# G32R501 register map
Vendor: Geehy Semiconductor Co., Ltd.; Series: G32R5; File version: 1.0
CPU: CM55 r0p1, little endian, MPU, FPU, double-precision FPU, DSP, VTOR, 4 interrupt priority bits
Registers are 32-bit, read-write, reset 0x0 unless marked. A register's access mark holds for its fields unless they carry their own. Offsets are from the block's base; [hi:lo] are bit positions; {n}, {i} and the like mark numbered series; 'fields as' and 'values as' point back to an identical list.

## PWM1 — Pulse Width Modulator
Base 0x40000000
Same registers: PWM2 0x40000400, PWM3 0x40000800, PWM4 0x40000C00, PWM5 0x40001000, PWM6 0x40001400, PWM7 0x40001800, PWM8 0x40001C00
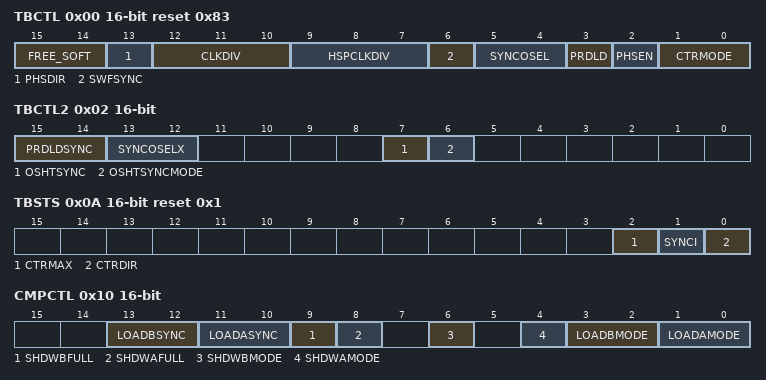
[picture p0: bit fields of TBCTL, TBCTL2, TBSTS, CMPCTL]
0x00 TBCTL 16-bit reset 0x83 — Time Base Control Register
  [15:14] FREE_SOFT — Emulation Mode Bits.
  [13] PHSDIR — Phase Direction Bit
  [12:10] CLKDIV — Time Base Clock Pre-Scale Bits
  [9:7] HSPCLKDIV — High Speed Time Base Clock Pre-Scale Bits
  [6] SWFSYNC — Software Forced Sync Pulse
  [5:4] SYNCOSEL — Sync Output Select
  [3] PRDLD — Active Period Reg Load from Shadow Select
  [2] PHSEN — Counter Reg Load from Phase Reg Enable
  [1:0] CTRMODE — Counter Mode
0x02 TBCTL2 16-bit — Time Base Control Register 2
  [15:14] PRDLDSYNC — Shadow to Active Period on SYNC event
  [13:12] SYNCOSELX — Extended selection bits for SYNCOUT
  [7] OSHTSYNC — Oneshot sync bit
  [6] OSHTSYNCMODE — Oneshot sync enable bit
0x08 TBCTR 16-bit — Time Base Counter Register
0x0A TBSTS 16-bit reset 0x1 — Time Base Status Register
  [2] CTRMAX — Time-Base Counter Max Latched Status Bit
  [1] SYNCI — Input Synchronization Latched Status Bit
  [0] CTRDIR ro — Time Base Counter Direction Status Bit
0x10 CMPCTL 16-bit — Counter Compare Control Register
  [13:12] LOADBSYNC — Shadow to Active CMPB Register Load on SYNC event
  [11:10] LOADASYNC — Shadow to Active CMPA Register Load on SYNC event
  [9] SHDWBFULL ro — Counter-compare B (CMPB) Shadow Register Full Status Flag
  [8] SHDWAFULL ro — Counter-compare A (CMPA) Shadow Register Full Status Flag
  [6] SHDWBMODE — Counter-compare B (CMPB) Register Operating Mode
  [4] SHDWAMODE — Counter-compare A (CMPA) Register Operating Mode
  [3:2] LOADBMODE — Active Counter-Compare B (CMPB) Load From Shadow Select Mode
  [1:0] LOADAMODE — Active Counter-Compare A (CMPA) Load From Shadow Select Mode
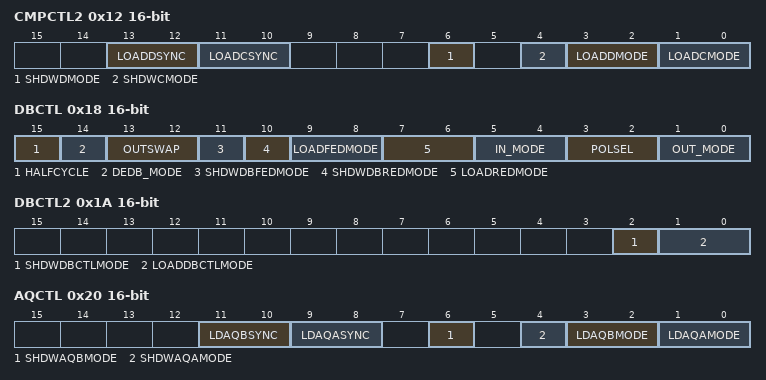
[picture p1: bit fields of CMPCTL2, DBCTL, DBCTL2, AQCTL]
0x12 CMPCTL2 16-bit — Counter Compare Control Register 2
  [13:12] LOADDSYNC — Shadow to Active CMPD Register Load on SYNC event
  [11:10] LOADCSYNC — Shadow to Active CMPC Register Load on SYNC event
  [6] SHDWDMODE — Counter-Compare D Register Operating Mode
  [4] SHDWCMODE — Counter-Compare C Register Operating Mode
  [3:2] LOADDMODE — Active Counter-Compare D (CMPD) Load from Shadow Select Mode
  [1:0] LOADCMODE — Active Counter-Compare C (CMPC) Load from Shadow Select Mode
0x18 DBCTL 16-bit — Dead-Band Generator Control Register
  [15] HALFCYCLE — Half Cycle Clocking Enable Bit
  [14] DEDB_MODE — Dead Band Dual-Edge B Mode Control (S8 switch)
  [13:12] OUTSWAP — Dead Band Output Swap Control
  [11] SHDWDBFEDMODE — FED Dead-Band Load Mode
  [10] SHDWDBREDMODE — RED Dead-Band Load Mode
  [9:8] LOADFEDMODE — Active DBFED Load from Shadow Select Mode
  [7:6] LOADREDMODE — Active DBRED Load from Shadow Select Mode
  [5:4] IN_MODE — Dead-Band Input Mode Control
  [3:2] POLSEL — Polarity Select Control
  [1:0] OUT_MODE — Dead-Band Output Mode Control
0x1A DBCTL2 16-bit — Dead-Band Generator Control Register 2
  [2] SHDWDBCTLMODE — DBCTL Load Mode
  [1:0] LOADDBCTLMODE — Active DBCTL Load from Shadow Select Mode
0x20 AQCTL 16-bit — Action Qualifier Control Register
  [11:10] LDAQBSYNC — Shadow to Active AQCTLB Register Load on SYNC event
  [9:8] LDAQASYNC — Shadow to Active AQCTLA Register Load on SYNC event
  [6] SHDWAQBMODE — Action Qualifier B Register operating mode
  [4] SHDWAQAMODE — Action Qualifier A Register operating mode
  [3:2] LDAQBMODE — Active Action Qualifier B Load from Shadow Select Mode
  [1:0] LDAQAMODE — Active Action Qualifier A Load from Shadow Select Mode
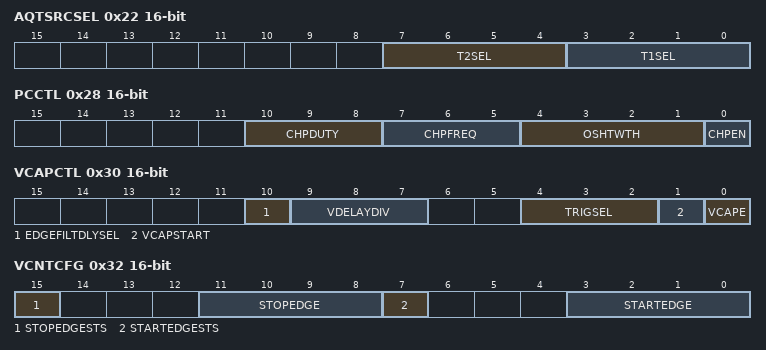
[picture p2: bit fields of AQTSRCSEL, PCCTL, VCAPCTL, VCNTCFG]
0x22 AQTSRCSEL 16-bit — Action Qualifier Trigger Event Source Select Register
  [7:4] T2SEL — T2 Event Source Select Bits
  [3:0] T1SEL — T1 Event Source Select Bits
0x28 PCCTL 16-bit — PWM Chopper Control Register
  [10:8] CHPDUTY — Chopping Clock Duty Cycle
  [7:5] CHPFREQ — Chopping Clock Frequency
  [4:1] OSHTWTH — One-Shot Pulse Width
  [0] CHPEN — PWM-Chopping Enable
0x30 VCAPCTL 16-bit — Valley Capture Control Register
  [10] EDGEFILTDLYSEL — Valley Switching Mode Delay Selection
  [9:7] VDELAYDIV — Valley Delay Mode Divide Enable
  [4:2] TRIGSEL — Status of Numbered of Captured Events
  [1] VCAPSTART — Valley Capture Start
  [0] VCAPE — Valley Capture Enable/Disable
0x32 VCNTCFG 16-bit — Valley Counter Config Register
  [15] STOPEDGESTS ro — Stop Edge Status Bit
  [11:8] STOPEDGE — Counter Stop Edge Selection
  [7] STARTEDGESTS ro — Start Edge Status Bit
  [3:0] STARTEDGE — Counter Start Edge Selection
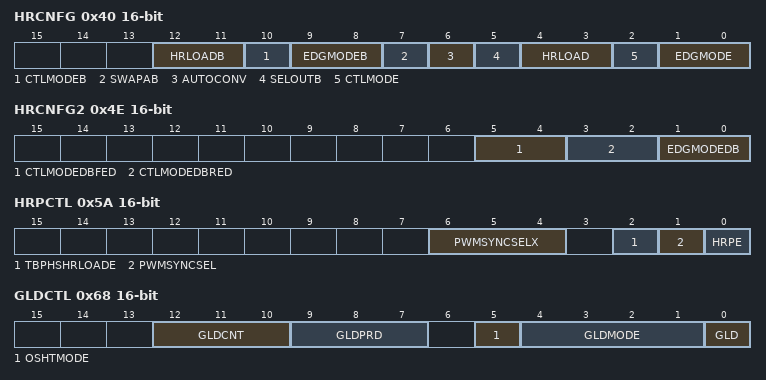
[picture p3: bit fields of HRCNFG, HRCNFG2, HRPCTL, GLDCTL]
0x40 HRCNFG 16-bit — HRPWM Configuration Register
  [12:11] HRLOADB — Shadow Mode Bit
  [10] CTLMODEB — Control Mode Bits
  [9:8] EDGMODEB — Edge Mode Bits
  [7] SWAPAB — Swap PWM A & B Output Signals
  [6] AUTOCONV — Auto Convert Delay Line Value
  [5] SELOUTB — PWMxB Output Select Bit
  [4:3] HRLOAD — Shadow Mode Bit
  [2] CTLMODE — Control Mode Bits
  [1:0] EDGMODE — Edge Mode Bits
0x42 HRPWR 16-bit — HRPWM Power Register
  [15] CALPWRON — MEP Calibration Power Bits (only available on PWM1)
0x4C HRMSTEP 16-bit — HRPWM MEP Step Register
  [7:0] HRMSTEP — High Resolution MEP Step
0x4E HRCNFG2 16-bit — HRPWM Configuration 2 Register
  [5:4] CTLMODEDBFED — Shadow Mode Bit - selection should match DBCTL LOADFEDMODE
  [3:2] CTLMODEDBRED — Shadow Mode Bit - selection should match DBCTL LOADREDMODE
  [1:0] EDGMODEDB — Edge Mode Bits
0x5A HRPCTL 16-bit — High Resolution Period Control Register
  [6:4] PWMSYNCSELX — Extended selection bits for PWMSYNCPER
  [2] TBPHSHRLOADE — TBPHSHR Load Enable
  [1] PWMSYNCSEL — PWMSYNC Source Select Bit
  [0] HRPE — High Resolution Period Enable Bit
0x5C TRREM 16-bit — HRPWM High Resolution Remainder Register
  [10:0] TRREM — Translator Remainder Bits
0x68 GLDCTL 16-bit — Global PWM Load Control Register
  [12:10] GLDCNT ro — Global Load Strobe Counter Register
  [9:7] GLDPRD — Global Load Strobe Period Select Register
  [5] OSHTMODE — One Shot Load Mode Control Bit
  [4:1] GLDMODE — Global Load Pulse selection for Shadow to Active Mode Reloads
  [0] GLD — Global Shadow to Active Load Event Control
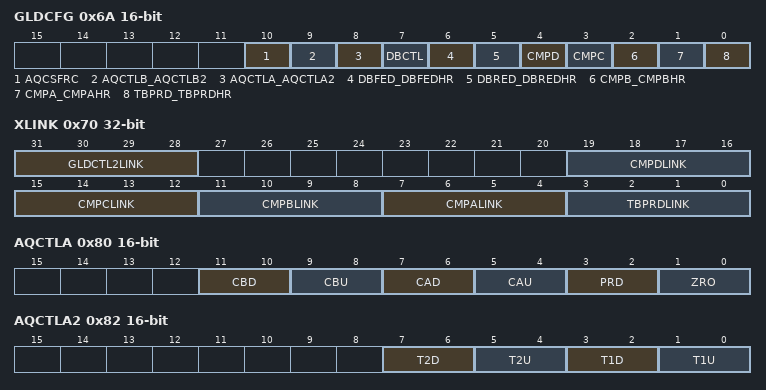
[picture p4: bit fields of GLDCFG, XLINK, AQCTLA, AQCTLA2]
0x6A GLDCFG 16-bit — Global PWM Load Config Register
  [10] AQCSFRC — Global load event configuration for AQCSFRC
  [9] AQCTLB_AQCTLB2 — Global load event configuration for AQCTLB_AQCTLB2
  [8] AQCTLA_AQCTLA2 — Global load event configuration for AQCTLA_AQCTLA2
  [7] DBCTL — Global load event configuration for DBCTL
  [6] DBFED_DBFEDHR — Global load event configuration for DBFED_DBFEDHR
  [5] DBRED_DBREDHR — Global load event configuration for DBRED_DBREDHR
  [4] CMPD — Global load event configuration for CMPD
  [3] CMPC — Global load event configuration for CMPC
  [2] CMPB_CMPBHR — Global load event configuration for CMPB_CMPBHR
  [1] CMPA_CMPAHR — Global load event configuration for CMPA_CMPAHR
  [0] TBPRD_TBPRDHR — Global load event configuration for TBPRD_TBPRDHR
0x70 XLINK — PWMx Link Register
  [31:28] GLDCTL2LINK — GLDCTL2 Link Bits
  [19:16] CMPDLINK — CMPD Link Bits
  [15:12] CMPCLINK — CMPC Link Bits
  [11:8] CMPBLINK — CMPB_CMPBHR Link Bits
  [7:4] CMPALINK — CMPA_CMPAHR Link Bits
  [3:0] TBPRDLINK — TBPRD_TBPRDHR Link Bits
0x80 AQCTLA 16-bit — Action Qualifier Control Register For Output A
  [11:10] CBD — Action When TBCTR = CMPB on Down Count
  [9:8] CBU — Action When TBCTR = CMPB on Up Count
  [7:6] CAD — Action When TBCTR = CMPA on Down Count
  [5:4] CAU — Action When TBCTR = CMPA on Up Count
  [3:2] PRD — Action When TBCTR = TBPRD
  [1:0] ZRO — Action When TBCTR = 0
0x82 AQCTLA2 16-bit — Additional Action Qualifier Control Register For Output A
  [7:6] T2D — Action when event occurs on T2 in DOWN-Count
  [5:4] T2U — Action when event occurs on T2 in UP-Count
  [3:2] T1D — Action when event occurs on T1 in DOWN-Count
  [1:0] T1U — Action when event occurs on T1 in UP-Count
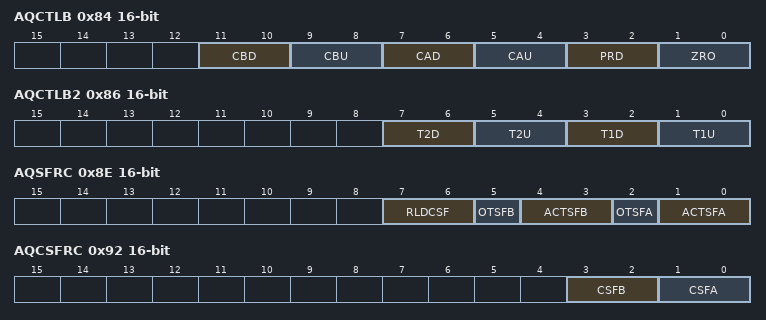
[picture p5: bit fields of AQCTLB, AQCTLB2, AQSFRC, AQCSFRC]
0x84 AQCTLB 16-bit — Action Qualifier Control Register For Output B
  fields as AQCTLA
0x86 AQCTLB2 16-bit — Additional Action Qualifier Control Register For Output B
  fields as AQCTLA2
0x8E AQSFRC 16-bit — Action Qualifier Software Force Register
  [7:6] RLDCSF — AQCSFRC Active Register Reload From Shadow Options
  [5] OTSFB — One-Time Software Forced Event on Output B
  [4:3] ACTSFB — Action When One-Time Software Force B is Invoked
  [2] OTSFA — One-Time Software Forced Event on Output A
  [1:0] ACTSFA — Action When One-Time Software Force A Is Invoked
0x92 AQCSFRC 16-bit — Action Qualifier Continuous S/W Force Register
  [3:2] CSFB — Continuous Software Force on Output B
  [1:0] CSFA — Continuous Software Force on Output A
0xA0 DBREDHR 16-bit — Dead-Band Generator Rising Edge Delay High Resolution Mirror Register
  [15:9] DBREDHR — Dead Band Rising Edge Delay High Resolution Bits
0xA2 DBRED 16-bit — Dead-Band Generator Rising Edge Delay High Resolution Mirror Register
  [13:0] DBRED — Rising edge delay value
0xA4 DBFEDHR 16-bit — Dead-Band Generator Falling Edge Delay High Resolution Register
  [15:9] DBFEDHR — Dead Band Falling Edge Delay High Resolution Bits
0xA6 DBFED 16-bit — Dead-Band Generator Falling Edge Delay Count Register
  [13:0] DBFED — Falling Edge Delay Count
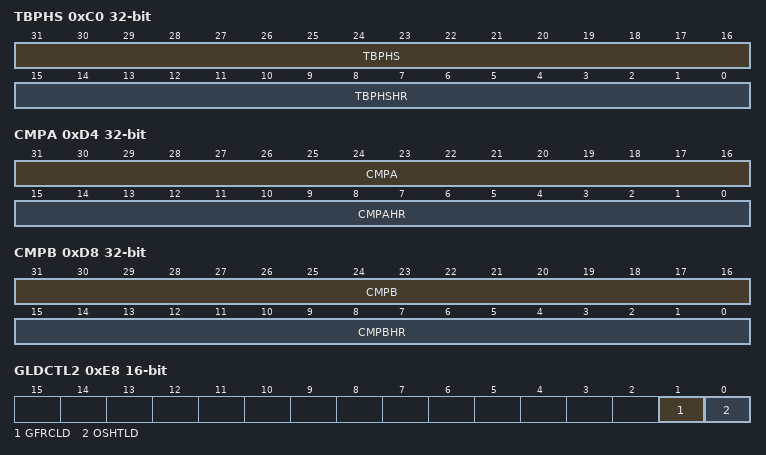
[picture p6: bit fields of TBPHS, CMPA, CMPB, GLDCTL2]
0xC0 TBPHS — Time Base Phase High
  [31:16] TBPHS — Phase Offset Register
  [15:0] TBPHSHR — Phase Offset (High Resolution) Register.
0xC4 TBPRDHR 16-bit — Time Base Period High Resolution Register
  [15:0] TBPRDHR — Period High Resolution Bits
0xC6 TBPRD 16-bit — Time Base Period Register
0xD4 CMPA — Counter Compare A Register
  [31:16] CMPA — Compare A Register
  [15:0] CMPAHR — Compare A HRPWM Extension Register
0xD8 CMPB — Compare B Register
  [31:16] CMPB — Compare B Register
  [15:0] CMPBHR — Compare B High Resolution Bits
0xDE CMPC 16-bit — Counter Compare C Register
  [15:0] CMPC — Compare C Register
0xE2 CMPD 16-bit — Counter Compare D Register
  [15:0] CMPD — Compare D Register
0xE8 GLDCTL2 16-bit — Global PWM Load Control Register 2
  [1] GFRCLD — Force Load Event in One Shot Mode
  [0] OSHTLD — Enable Reload Event in One Shot Mode
0xEE SWVDELVAL 16-bit — Software Valley Mode Delay Register
  [15:0] SWVDELVAL — Software Valley Delay Value Register
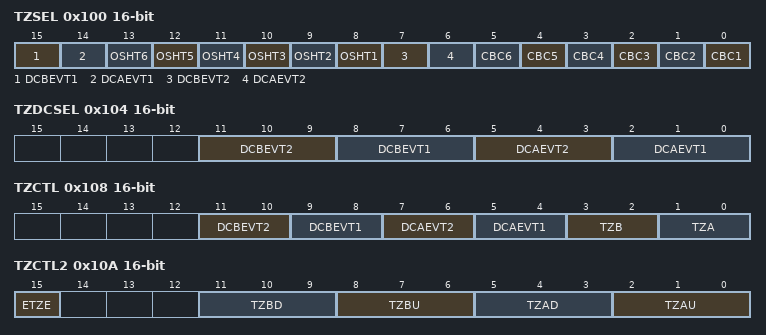
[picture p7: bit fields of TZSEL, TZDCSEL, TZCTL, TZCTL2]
0x100 TZSEL 16-bit — Trip Zone Select Register
  [15] DCBEVT1 — Digital Compare Output B Event 1 Select
  [14] DCAEVT1 — Digital Compare Output A Event 1 Select
  [n+7] OSHT{n} (n=1..6) — Trip-zone {n} (TZ{n}) Select
  [7] DCBEVT2 — Digital Compare Output B Event 2 Select
  [6] DCAEVT2 — Digital Compare Output A Event 2 Select
  [n-1] CBC{n} (n=1..6) — Trip-zone {n} (TZ{n}) Select
0x104 TZDCSEL 16-bit — Trip Zone Digital Comparator Select Register
  [11:9] DCBEVT2 — Digital Compare Output B Event 2 Selection
  [8:6] DCBEVT1 — Digital Compare Output B Event 1 Selection
  [5:3] DCAEVT2 — Digital Compare Output A Event 2 Selection
  [2:0] DCAEVT1 — Digital Compare Output A Event 1 Selection
0x108 TZCTL 16-bit — Trip Zone Control Register
  [11:10] DCBEVT2 — Digital Compare Output B Event 2 Action On PWMxB
  [9:8] DCBEVT1 — Digital Compare Output B Event 1 Action On PWMxB
  [7:6] DCAEVT2 — Digital Compare Output A Event 2 Action On PWMxA
  [5:4] DCAEVT1 — Digital Compare Output A Event 1 Action On PWMxA
  [3:2] TZB — TZ1 to TZ6, DCAEVT1/2, DCBEVT1/2Trip Action On PWMxB
  [1:0] TZA — TZ1 to TZ6, DCAEVT1/2, DCBEVT1/2Trip Action On PWMxA
0x10A TZCTL2 16-bit — Additional Trip Zone Control Register
  [15] ETZE — TZCTL2 Enable
  [11:9] TZBD — TZ1 to TZ6, DCAEVT1/2, DCBEVT1/2 Trip Action On PWMxB
  [8:6] TZBU — TZ1 to TZ6, DCAEVT1/2, DCBEVT1/2 Trip Action On PWMxB
  [5:3] TZAD — TZ1 to TZ6, DCAEVT1/2, DCBEVT1/2 Trip Action On PWMxA
  [2:0] TZAU — TZ1 to TZ6, DCAEVT1/2, DCBEVT1/2 Trip Action On PWMxA
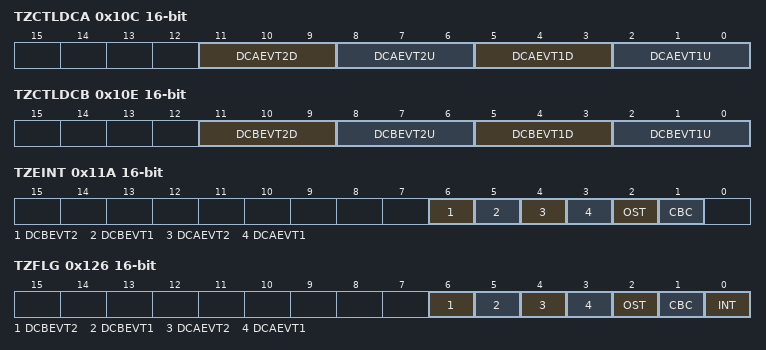
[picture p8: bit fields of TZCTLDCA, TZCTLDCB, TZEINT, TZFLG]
0x10C TZCTLDCA 16-bit — Trip Zone Control Register Digital Compare A
  [11:9] DCAEVT2D — Digital Compare Output A Event 2 Action On PWMxA while Count direction is DOWN
  [8:6] DCAEVT2U — Digital Compare Output A Event 2 Action On PWMxA while Count direction is UP
  [5:3] DCAEVT1D — Digital Compare Output A Event 1 Action On PWMxA while Count direction is DOWN
  [2:0] DCAEVT1U — Digital Compare Output A Event 1 Action On PWMxA while Count direction is UP
0x10E TZCTLDCB 16-bit — Trip Zone Control Register Digital Compare B
  [11:9] DCBEVT2D — Digital Compare Output A Event 2 Action On PWMxB while Count direction is DOWN
  [8:6] DCBEVT2U — Digital Compare Output A Event 2 Action On PWMxB while Count direction is UP
  [5:3] DCBEVT1D — Digital Compare Output A Event 1 Action On PWMxB while Count direction is DOWN
  [2:0] DCBEVT1U — Digital Compare Output A Event 1 Action On PWMxB while Count direction is UP
0x11A TZEINT 16-bit — Trip Zone Enable Interrupt Register
  [6] DCBEVT2 — Digital Compare Output B Event 2 Interrupt Enable
  [5] DCBEVT1 — Digital Compare Output B Event 1 Interrupt Enable
  [4] DCAEVT2 — Digital Compare Output A Event 2 Interrupt Enable
  [3] DCAEVT1 — Digital Compare Output A Event 1 Interrupt Enable
  [2] OST — Trip-zone One-Shot Interrupt Enable
  [1] CBC — Trip-zone Cycle-by-Cycle Interrupt Enable
0x126 TZFLG 16-bit ro — Trip Zone Flag Register
  [6] DCBEVT2 — Latched Status Flag for Digital Compare Output B Event 2
  [5] DCBEVT1 — Latched Status Flag for Digital Compare Output B Event 1
  [4] DCAEVT2 — Latched Status Flag for Digital Compare Output A Event 2
  [3] DCAEVT1 — Latched Status Flag for Digital Compare Output A Event 1
  [2] OST — Latched Status Flag for A One-Shot Trip Event
  [1] CBC — Latched Status Flag for Cycle-By-Cycle Trip Event
  [0] INT — Latched Trip Interrupt Status Flag
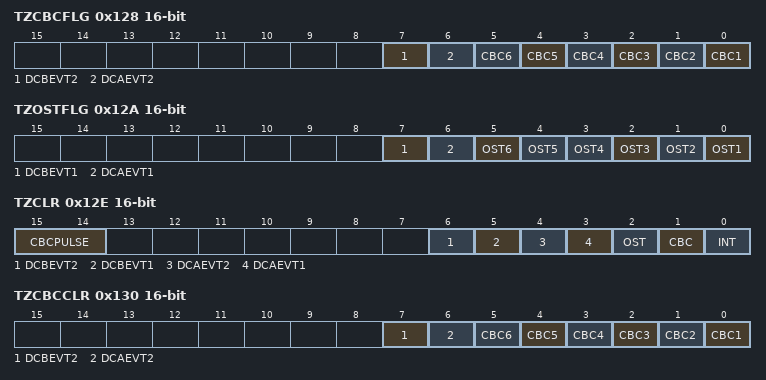
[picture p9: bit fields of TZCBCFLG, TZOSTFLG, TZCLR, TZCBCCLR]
0x128 TZCBCFLG 16-bit ro — Trip Zone CBC Flag Register
  [7] DCBEVT2 — Latched Status Flag for Digital Compare B Output Event 2 Trip Latch
  [6] DCAEVT2 — Latched Status Flag for Digital Compare A Output Event 2 Trip Latch
  [n-1] CBC{n} (n=1..6) — Latched Status Flag for CBC{n} Trip Latch
0x12A TZOSTFLG 16-bit ro — Trip Zone OST Flag Register
  [7] DCBEVT1 — Latched Status Flag for Digital Compare B Output Event 1 Trip Latch
  [6] DCAEVT1 — Latched Status Flag for Digital Compare A Output Event 1 Trip Latch
  [5] OST6 — Latched Status Flag for OST6 Trip Latch
  [4] OST5 — Latched Status Flag for OST5Trip Latch
  [n-1] OST{n} (n=1..4) — Latched Status Flag for OST{n} Trip Latch
0x12E TZCLR 16-bit — Trip Zone Clear Register
  [15:14] CBCPULSE — Clear Pulse for Cycle-By-Cycle (CBC) Trip Latch
  [6] DCBEVT2 — Clear Flag for Digital Compare Output B Event 2
  [5] DCBEVT1 — Clear Flag for Digital Compare Output B Event 1
  [4] DCAEVT2 — Clear Flag for Digital Compare Output A Event 2
  [3] DCAEVT1 — Clear Flag for Digital Compare Output A Event 1
  [2] OST — Clear Flag for One-Shot Trip (OST) Latch
  [1] CBC — Clear Flag for Cycle-By-Cycle (CBC) Trip Latch
  [0] INT — Global Interrupt Clear Flag
0x130 TZCBCCLR 16-bit — Trip Zone CBC Clear Register
  [7] DCBEVT2 — Clear Flag for Digital Compare Output B Event 2 selected for CBC
  [6] DCAEVT2 — Clear Flag for Digital Compare Output A Event 2 selected for CBC
  [n-1] CBC{n} (n=1..6) — Clear Flag for Cycle-By-Cycle (CBC{n}) Trip Latch
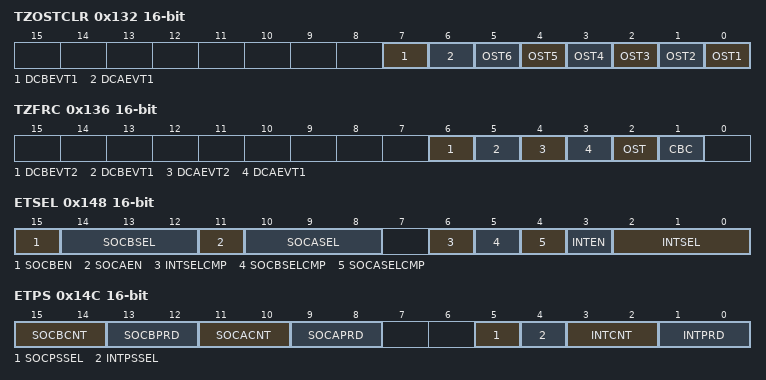
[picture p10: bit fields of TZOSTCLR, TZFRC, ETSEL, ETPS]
0x132 TZOSTCLR 16-bit — Trip Zone OST Clear Register
  [7] DCBEVT1 — Clear Flag for Digital Compare Output B Event 1 selected for OST
  [6] DCAEVT1 — Clear Flag for Digital Compare Output A Event 1 selected for OST
  [n-1] OST{n} (n=1..6) — Clear Flag for Oneshot (OST{n}) Trip Latch
0x136 TZFRC 16-bit — Trip Zone Force Register
  [6] DCBEVT2 — Force Flag for Digital Compare Output B Event 2
  [5] DCBEVT1 — Force Flag for Digital Compare Output B Event 1
  [4] DCAEVT2 — Force Flag for Digital Compare Output A Event 2
  [3] DCAEVT1 — Force Flag for Digital Compare Output A Event 1
  [2] OST — Force a One-Shot Trip Event via Software
  [1] CBC — Force a Cycle-by-Cycle Trip Event via Software
0x148 ETSEL 16-bit — Event Trigger Selection Register
  [15] SOCBEN — Enable the ADC Start of Conversion B (PWMxSOCB) Pulse
  [14:12] SOCBSEL — PWMxSOCB Selection Options
  [11] SOCAEN — Enable the ADC Start of Conversion A (PWMxSOCA) Pulse
  [10:8] SOCASEL — PWMxSOCA Selection Options
  [6] INTSELCMP — PWMxINT Compare Register Selection Options
  [5] SOCBSELCMP — PWMxSOCB Compare Register Selection Options
  [4] SOCASELCMP — PWMxSOCA Compare Register Selection Options
  [3] INTEN — Enable PWM Interrupt (PWMx_INT) Generation
  [2:0] INTSEL — PWM Interrupt (PWMx_INT) Selection Options
0x14C ETPS 16-bit — Event Trigger Pre-Scale Register
  [15:14] SOCBCNT ro — PWM ADC Start-of-Conversion B Event (PWMxSOCB) Counter Register
  [13:12] SOCBPRD — PWM ADC Start-of-Conversion B Event (PWMxSOCB) Period Select
  [11:10] SOCACNT ro — PWM ADC Start-of-Conversion A Event (PWMxSOCA) Counter Register
  [9:8] SOCAPRD — PWM ADC Start-of-Conversion A Event (PWMxSOCA) Period Select
  [5] SOCPSSEL — PWMxSOC A/B Pre-Scale Selection Bits
  [4] INTPSSEL — PWMxINTn Pre-Scale Selection Bits
  [3:2] INTCNT ro — PWM Interrupt Event (PWMx_INT) Counter Register
  [1:0] INTPRD — PWM Interrupt (PWMx_INT) Period Select
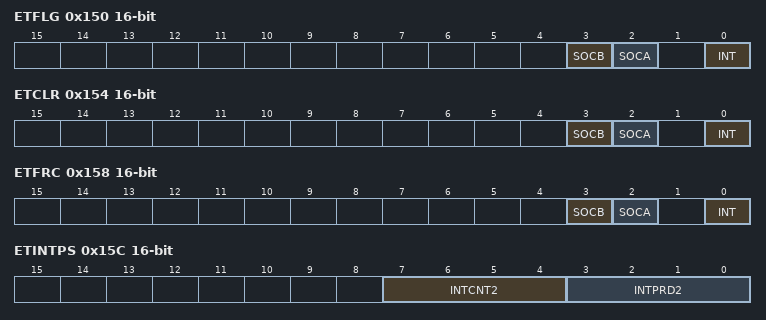
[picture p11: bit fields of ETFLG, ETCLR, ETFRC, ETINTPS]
0x150 ETFLG 16-bit ro — Event Trigger Flag Register
  [3] SOCB — Latched PWM ADC Start-of-Conversion A (PWMxSOCB) Status Flag
  [2] SOCA — Latched PWM ADC Start-of-Conversion A (PWMxSOCA) Status Flag
  [0] INT — Latched PWM Interrupt (PWMx_INT) Status Flag
0x154 ETCLR 16-bit — Event Trigger Clear Register
  [3] SOCB — PWM ADC Start-of-Conversion A (PWMxSOCB) Flag Clear Bit
  [2] SOCA — PWM ADC Start-of-Conversion A (PWMxSOCA) Flag Clear Bit
  [0] INT — PWM Interrupt (PWMx_INT) Flag Clear Bit
0x158 ETFRC 16-bit — Event Trigger Force Register
  [3] SOCB — SOCB Force Bit
  [2] SOCA — SOCA Force Bit
  [0] INT — INT Force Bit
0x15C ETINTPS 16-bit — Event-Trigger Interrupt Pre-Scale Register
  [7:4] INTCNT2 ro — PWMxINT Counter 2
  [3:0] INTPRD2 — PWMxINT Period 2 Select
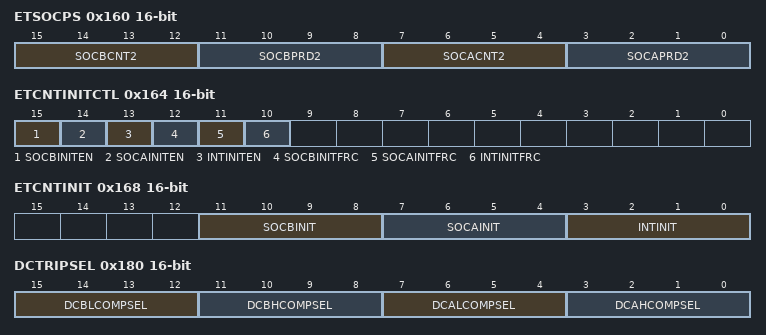
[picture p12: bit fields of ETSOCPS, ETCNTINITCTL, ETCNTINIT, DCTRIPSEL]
0x160 ETSOCPS 16-bit — Event-Trigger SOC Pre-Scale Register
  [15:12] SOCBCNT2 ro — PWMxSOCB Counter 2
  [11:8] SOCBPRD2 — PWMxSOCB Period 2 Select
  [7:4] SOCACNT2 ro — PWMxSOCA Counter 2
  [3:0] SOCAPRD2 — PWMxSOCA Period 2 Select
0x164 ETCNTINITCTL 16-bit — Event-Trigger Counter Initialization Control Register
  [15] SOCBINITEN — PWMxSOCB Counter 2 Initialization Enable
  [14] SOCAINITEN — PWMxSOCA Counter 2 Initialization Enable
  [13] INTINITEN — PWMxINT Counter 2 Initialization Enable
  [12] SOCBINITFRC — PWMxSOCB Counter 2 Initialization Force
  [11] SOCAINITFRC — PWMxSOCA Counter 2 Initialization Force
  [10] INTINITFRC — PWMxINT Counter 2 Initialization Force
0x168 ETCNTINIT 16-bit — Event-Trigger Counter Initialization Register
  [11:8] SOCBINIT — PWMxSOCB Counter 2 Initialization Bits
  [7:4] SOCAINIT — PWMxSOCA Counter 2 Initialization Bits
  [3:0] INTINIT — PWMxINT Counter 2 Initialization Bits
0x180 DCTRIPSEL 16-bit — Digital Compare Trip Select Register
  [15:12] DCBLCOMPSEL — Digital Compare B Low Input Select Bits
  [11:8] DCBHCOMPSEL — Digital Compare B High Input Select Bits
  [7:4] DCALCOMPSEL — Digital Compare A Low Input Select Bits
  [3:0] DCAHCOMPSEL — Digital Compare A High Input Select Bits
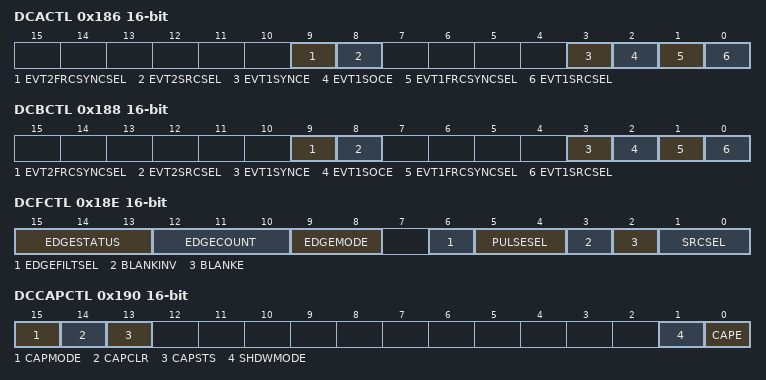
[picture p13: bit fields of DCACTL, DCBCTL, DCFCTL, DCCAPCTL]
0x186 DCACTL 16-bit — Digital Compare A Control Register
  [9] EVT2FRCSYNCSEL — DCAEVT2 Force Synchronization Signal Select
  [8] EVT2SRCSEL — DCAEVT2 Source Signal Select
  [3] EVT1SYNCE — DCAEVT1 SYNC, Enable/Disable
  [2] EVT1SOCE — DCAEVT1 SOC, Enable/Disable
  [1] EVT1FRCSYNCSEL — DCAEVT1 Force Synchronization Signal Select
  [0] EVT1SRCSEL — DCAEVT1 Source Signal Select
0x188 DCBCTL 16-bit — Digital Compare B Control Register
  [9] EVT2FRCSYNCSEL — DCBEVT2 Force Synchronization Signal Select
  [8] EVT2SRCSEL — DCBEVT2 Source Signal Select
  [3] EVT1SYNCE — DCBEVT1 SYNC, Enable/Disable
  [2] EVT1SOCE — DCBEVT1 SOC, Enable/Disable
  [1] EVT1FRCSYNCSEL — DCBEVT1 Force Synchronization Signal Select
  [0] EVT1SRCSEL — DCBEVT1 Source Signal Select
0x18E DCFCTL 16-bit — Digital Compare Filter Control Register
  [15:13] EDGESTATUS ro
  [12:10] EDGECOUNT
  [9:8] EDGEMODE — Edge Mode Select
  [6] EDGEFILTSEL — Edge Filter Select
  [5:4] PULSESEL — Pulse Select For Blanking & Capture Alignment
  [3] BLANKINV — Blanking Window Inversion
  [2] BLANKE — Blanking Window Enable/Disable
  [1:0] SRCSEL — Filter Block Signal Source Select
0x190 DCCAPCTL 16-bit — Digital Compare Capture Control Register
  [15] CAPMODE — Counter Capture Mode
  [14] CAPCLR — DC Capture Latched Status Clear Flag
  [13] CAPSTS ro — Latched Status Flag for Capture Event
  [1] SHDWMODE — TBCTR Counter Capture Shadow Select Mode
  [0] CAPE — TBCTR Counter Capture Enable/Disable
0x192 DCFOFFSET 16-bit — Digital Compare Filter Offset Register
  [15:0] DCFOFFSET — Blanking Window Offset
0x194 DCFOFFSETCNT 16-bit ro — Digital Compare Filter Offset Counter Register
  [15:0] DCFOFFSETCNT — Blanking Offset Counter
0x196 DCFWINDOW 16-bit — Digital Compare Filter Window Register
  [15:0] DCFWINDOW — Blanking Window Width
0x198 DCFWINDOWCNT 16-bit ro — Digital Compare Filter Window Counter Register
  [15:0] DCFWINDOWCNT — Blanking Window Counter
0x19E DCCAP 16-bit ro — Digital Compare Counter Capture Register
  [15:0] DCCAP — Digital Compare Time-Base Counter Capture
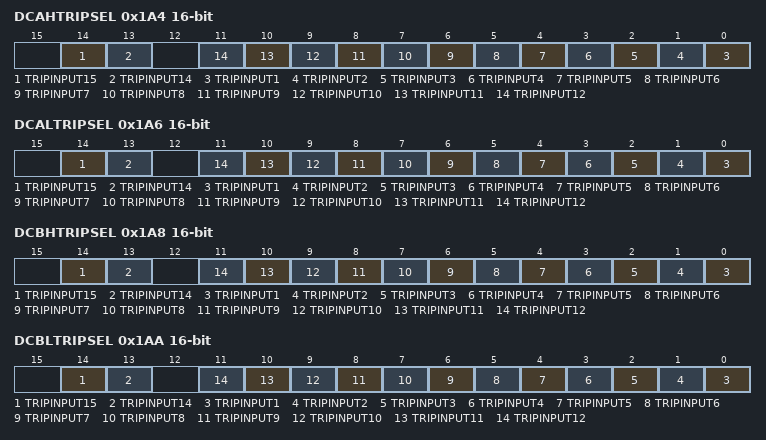
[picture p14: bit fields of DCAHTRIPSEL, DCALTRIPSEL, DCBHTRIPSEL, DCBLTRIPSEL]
0x1A4 DCAHTRIPSEL 16-bit — Digital Compare AH Trip Select
  [14] TRIPINPUT15, [13] TRIPINPUT14, [n-1] TRIPINPUT{n} (n=1..12)
0x1A6 DCALTRIPSEL 16-bit — Digital Compare AL Trip Select
  [14] TRIPINPUT15, [13] TRIPINPUT14, [n-1] TRIPINPUT{n} (n=1..12)
0x1A8 DCBHTRIPSEL 16-bit — Digital Compare BH Trip Select
  [14] TRIPINPUT15, [13] TRIPINPUT14, [n-1] TRIPINPUT{n} (n=1..12)
0x1AA DCBLTRIPSEL 16-bit — Digital Compare BL Trip Select
  [14] TRIPINPUT15, [13] TRIPINPUT14, [n-1] TRIPINPUT{n} (n=1..12)
0x1F4 LOCK — PWM Lock Register
  [31:16] KEY
  [4] DCLOCK — Digital Compare Register Set Lock
  [3] TZCLRLOCK — TripZone Clear Register Set Lock
  [2] TZCFGLOCK — TripZone Register Set Lock
  [1] GLLOCK — Global Load Register Set Lock
  [0] HRLOCK — HRPWM Register Set Lock
0x1FA HWVDELVAL 16-bit ro — Hardware Valley Mode Delay Register
  [15:0] HWVDELVAL — Hardware Valley Delay Value Register
0x1FC VCNTVAL 16-bit ro — Hardware Valley Counter Register
  [15:0] VCNTVAL — Valley Time Base Counter Register
